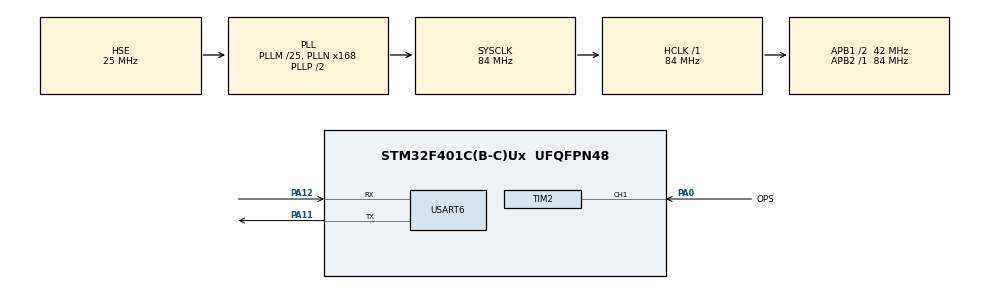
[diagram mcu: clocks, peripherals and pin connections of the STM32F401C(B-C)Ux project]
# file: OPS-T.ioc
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Mcu.Family=STM32F4
Mcu.Name=STM32F401C(B-C)Ux
Mcu.Package=UFQFPN48
NVIC.PriorityGroup=NVIC_PRIORITYGROUP_4
NVIC.TIM2_IRQn=true\:0\:0\:false\:false\:true\:true\:true\:true
PA0-WKUP.GPIO_Label=OPS
PA0-WKUP.Signal=S_TIM2_CH1_ETR
PA11.Mode=Asynchronous
PA11.Signal=USART6_TX
PA12.Mode=Asynchronous
PA12.Signal=USART6_RX
PA13.Mode=Serial_Wire
PA13.Signal=SYS_JTMS-SWDIO
PA14.Mode=Serial_Wire
PA14.Signal=SYS_JTCK-SWCLK
PH0\ -\ OSC_IN.Mode=HSE-External-Oscillator
PH0\ -\ OSC_IN.Signal=RCC_OSC_IN
PH1\ -\ OSC_OUT.Mode=HSE-External-Oscillator
PH1\ -\ OSC_OUT.Signal=RCC_OSC_OUT
ProjectManager.HeapSize=0x200
ProjectManager.StackSize=0x400
ProjectManager.TargetToolchain=STM32CubeIDE
RCC.48MHZClocksFreq_Value=42000000
RCC.AHBFreq_Value=84000000
RCC.APB1CLKDivider=RCC_HCLK_DIV2
RCC.APB1Freq_Value=42000000
RCC.APB1TimFreq_Value=84000000
RCC.APB2Freq_Value=84000000
RCC.APB2TimFreq_Value=84000000
RCC.CortexFreq_Value=84000000
RCC.HCLKFreq_Value=84000000
RCC.HSE_VALUE=25000000
RCC.HSI_VALUE=16000000
RCC.LSE_VALUE=32768
RCC.PLLM=25
RCC.PLLN=168
RCC.PLLSourceVirtual=RCC_PLLSOURCE_HSE
RCC.SYSCLKFreq_VALUE=84000000
RCC.SYSCLKSource=RCC_SYSCLKSOURCE_PLLCLK
RCC.VCOOutputFreq_Value=168000000
SH.S_TIM2_CH1_ETR.0=TIM2_CH1,PWM_Input_1
USART6.VirtualMode=VM_ASYNC
board=custom

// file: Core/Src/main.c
/* USER CODE BEGIN Header */
/**
 ******************************************************************************
 * @file           : main.c
 * @brief          : Main program body
 ******************************************************************************
 * @attention
 *
 * Copyright (c) 2025 STMicroelectronics.
 * All rights reserved.
 *
 * This software is licensed under terms that can be found in the LICENSE file
 * in the root directory of this software component.
 * If no LICENSE file comes with this software, it is provided AS-IS.
 *
 ******************************************************************************
 */
/* USER CODE END Header */
#include "main.h"

/* USER CODE BEGIN Includes */
#include <stdio.h>
#include <string.h>
/* USER CODE END Includes */

TIM_HandleTypeDef htim2;

UART_HandleTypeDef huart6;

/* USER CODE BEGIN PV */
uint8_t data_block[] = "Hello world\n";

// timer stuff:
float tick_time_sec = 0;
float tick_time_micros = 0;

/* USER CODE END PV */

void SystemClock_Config(void);
static void MX_GPIO_Init(void);
static void MX_USART6_UART_Init(void);
static void MX_TIM2_Init(void);
/* USER CODE BEGIN PFP */
void set_timer_globals(void);
float calculate_temperature(uint32_t ticks_count);
float calculate_pressure(uint32_t ticks_count);
eStatus calculate_sensor_status(uint32_t ticks_count);
/* USER CODE END PFP */

/* USER CODE BEGIN 0 */

sOps sensor1;

/* USER CODE END 0 */

int main(void) {

	/* MCU Configuration--------------------------------------------------------*/

	/* Reset of all peripherals, Initializes the Flash interface and the Systick. */
	HAL_Init();

	/* Configure the system clock */
	SystemClock_Config();

	/* Initialize all configured peripherals */
	MX_GPIO_Init();
	MX_USART6_UART_Init();
	MX_TIM2_Init();
	/* USER CODE BEGIN 2 */

	uint8_t sensor_data[128];
	set_timer_globals();

	sensor1.receiveStatus = waitForStatus;

	HAL_TIM_IC_Start_IT(&htim2, TIM_CHANNEL_1);
	HAL_TIM_IC_Start(&htim2, TIM_CHANNEL_2);

	/* USER CODE END 2 */

	/* Infinite loop */
	/* USER CODE BEGIN WHILE */
	while (1) {
		// HAL_UART_Transmit(&huart6, data_block, sizeof(data_block) - 1, 100);
		sprintf((char*) sensor_data, "Status: %d, Temperature: %.2f °C, Pressure: %.2f Bar\r\n",
				calculate_sensor_status(sensor1.statusTicks), calculate_temperature(sensor1.temperatureTicks),
				calculate_pressure(sensor1.pressureTicks));

		HAL_UART_Transmit(&huart6, (uint8_t*) sensor_data, strlen((char*) sensor_data), HAL_MAX_DELAY);

		HAL_Delay(1000);
		/* USER CODE END WHILE */

	}
}

void SystemClock_Config(void) {
	RCC_OscInitTypeDef RCC_OscInitStruct = { 0 };
	RCC_ClkInitTypeDef RCC_ClkInitStruct = { 0 };

	/** Configure the main internal regulator output voltage
	 */
	__HAL_RCC_PWR_CLK_ENABLE();
	__HAL_PWR_VOLTAGESCALING_CONFIG(PWR_REGULATOR_VOLTAGE_SCALE2);

	/** Initializes the RCC Oscillators according to the specified parameters
	 * in the RCC_OscInitTypeDef structure.
	 */
	RCC_OscInitStruct.OscillatorType = RCC_OSCILLATORTYPE_HSE;
	RCC_OscInitStruct.HSEState = RCC_HSE_ON;
	RCC_OscInitStruct.PLL.PLLState = RCC_PLL_ON;
	RCC_OscInitStruct.PLL.PLLSource = RCC_PLLSOURCE_HSE;
	RCC_OscInitStruct.PLL.PLLM = 25;
	RCC_OscInitStruct.PLL.PLLN = 168;
	RCC_OscInitStruct.PLL.PLLP = RCC_PLLP_DIV2;
	RCC_OscInitStruct.PLL.PLLQ = 4;
	if (HAL_RCC_OscConfig(&RCC_OscInitStruct) != HAL_OK) {
		Error_Handler();
	}

	/** Initializes the CPU, AHB and APB buses clocks
	 */
	RCC_ClkInitStruct.ClockType = RCC_CLOCKTYPE_HCLK | RCC_CLOCKTYPE_SYSCLK | RCC_CLOCKTYPE_PCLK1 | RCC_CLOCKTYPE_PCLK2;
	RCC_ClkInitStruct.SYSCLKSource = RCC_SYSCLKSOURCE_PLLCLK;
	RCC_ClkInitStruct.AHBCLKDivider = RCC_SYSCLK_DIV1;
	RCC_ClkInitStruct.APB1CLKDivider = RCC_HCLK_DIV2;
	RCC_ClkInitStruct.APB2CLKDivider = RCC_HCLK_DIV1;

	if (HAL_RCC_ClockConfig(&RCC_ClkInitStruct, FLASH_LATENCY_2) != HAL_OK) {
		Error_Handler();
	}
}

static void MX_TIM2_Init(void) {

	TIM_SlaveConfigTypeDef sSlaveConfig = { 0 };
	TIM_IC_InitTypeDef sConfigIC = { 0 };
	TIM_MasterConfigTypeDef sMasterConfig = { 0 };

	htim2.Instance = TIM2;
	htim2.Init.Prescaler = 0;
	htim2.Init.CounterMode = TIM_COUNTERMODE_UP;
	htim2.Init.Period = 4294967295;
	htim2.Init.ClockDivision = TIM_CLOCKDIVISION_DIV1;
	htim2.Init.AutoReloadPreload = TIM_AUTORELOAD_PRELOAD_DISABLE;
	if (HAL_TIM_IC_Init(&htim2) != HAL_OK) {
		Error_Handler();
	}
	sSlaveConfig.SlaveMode = TIM_SLAVEMODE_RESET;
	sSlaveConfig.InputTrigger = TIM_TS_TI1FP1;
	sSlaveConfig.TriggerPolarity = TIM_INPUTCHANNELPOLARITY_RISING;
	sSlaveConfig.TriggerPrescaler = TIM_ICPSC_DIV1;
	sSlaveConfig.TriggerFilter = 0;
	if (HAL_TIM_SlaveConfigSynchro(&htim2, &sSlaveConfig) != HAL_OK) {
		Error_Handler();
	}
	sConfigIC.ICPolarity = TIM_INPUTCHANNELPOLARITY_RISING;
	sConfigIC.ICSelection = TIM_ICSELECTION_DIRECTTI;
	sConfigIC.ICPrescaler = TIM_ICPSC_DIV1;
	sConfigIC.ICFilter = 0;
	if (HAL_TIM_IC_ConfigChannel(&htim2, &sConfigIC, TIM_CHANNEL_1) != HAL_OK) {
		Error_Handler();
	}
	sConfigIC.ICPolarity = TIM_INPUTCHANNELPOLARITY_FALLING;
	sConfigIC.ICSelection = TIM_ICSELECTION_INDIRECTTI;
	if (HAL_TIM_IC_ConfigChannel(&htim2, &sConfigIC, TIM_CHANNEL_2) != HAL_OK) {
		Error_Handler();
	}
	sMasterConfig.MasterOutputTrigger = TIM_TRGO_RESET;
	sMasterConfig.MasterSlaveMode = TIM_MASTERSLAVEMODE_DISABLE;
	if (HAL_TIMEx_MasterConfigSynchronization(&htim2, &sMasterConfig) != HAL_OK) {
		Error_Handler();
	}

}

static void MX_USART6_UART_Init(void) {

	huart6.Instance = USART6;
	huart6.Init.BaudRate = 115200;
	huart6.Init.WordLength = UART_WORDLENGTH_8B;
	huart6.Init.StopBits = UART_STOPBITS_1;
	huart6.Init.Parity = UART_PARITY_NONE;
	huart6.Init.Mode = UART_MODE_TX_RX;
	huart6.Init.HwFlowCtl = UART_HWCONTROL_NONE;
	huart6.Init.OverSampling = UART_OVERSAMPLING_16;
	if (HAL_UART_Init(&huart6) != HAL_OK) {
		Error_Handler();
	}

}

static void MX_GPIO_Init(void) {

	/* GPIO Ports Clock Enable */
	__HAL_RCC_GPIOH_CLK_ENABLE();
	__HAL_RCC_GPIOA_CLK_ENABLE();

}

/* USER CODE BEGIN 4 */

void set_timer_globals(void) {
	uint32_t apb1_frequency = HAL_RCC_GetPCLK1Freq();
	uint32_t timclk;

	if ((RCC->CFGR & RCC_CFGR_PPRE1) != RCC_CFGR_PPRE1_DIV1)
		timclk = apb1_frequency * 2;
	else
		timclk = apb1_frequency;

	uint32_t prescaler = htim2.Init.Prescaler;
	float timer_freq = (float) timclk / (prescaler + 1);
	tick_time_sec = 1.0f / timer_freq;  // seconds per tick
	tick_time_micros = tick_time_sec * 1000000;  // seconds per tick
}

float calculate_temperature(uint32_t ticks_count) {
	float time_us = ticks_count * tick_time_micros;

	return (time_us - 896.0f) / 19.2f;
}

float calculate_pressure(uint32_t ticks_count) {
	float time_us = ticks_count * tick_time_micros;
	return (time_us + 64.0f) / 384.0f;
}

eStatus calculate_sensor_status(uint32_t ticks_count) {
	// in status field is the tolerance +/- 25µs
	float time_us = ticks_count * tick_time_micros;
	eStatus retVal;

	if (time_us >= 231 && time_us <= 281)
		retVal = okStatus;

	if (time_us >= 359 && time_us <= 409)
		retVal = pressureFailure;

	if (time_us >= 487 && time_us <= 537)
		retVal = temperatureFailure;

	if (time_us >= 615 && time_us <= 665)
		retVal = hardwareFailure;

	return retVal;

}

void HAL_TIM_IC_CaptureCallback(TIM_HandleTypeDef *htim) {

	if (htim->Instance == TIM2) {
		/*
		 * timer_channel_1 fires the interrupt
		 * timer_channel_1 will be triggered on RISING edge (package length)
		 * timer_channel_2 will be triggered on FALLING edge (pwm value)
		 *
		 */
		uint32_t ticks_full = HAL_TIM_ReadCapturedValue(htim, TIM_CHANNEL_1) + 2;	// time between two rising edges
		uint32_t ticks_high = HAL_TIM_ReadCapturedValue(htim, TIM_CHANNEL_2) + 2;	// time between rising and falling edges

		float time_full = ticks_full * tick_time_micros;

		if (time_full > 1000 && time_full < 1100) {
			// we received the status field of the message
			sensor1.statusTicks = ticks_high;
			sensor1.receiveStatus = statusReceived;
		}

		else if (time_full > 3900 && sensor1.receiveStatus == statusReceived) {
			// now we are receiving the temperature field of the message
			sensor1.temperatureTicks = ticks_high;
			sensor1.receiveStatus = temperatureReceived;
		}

		else if (time_full > 3900 && sensor1.receiveStatus == temperatureReceived) {
			// now we are receiving the pressure field of the message
			sensor1.pressureTicks = ticks_high;
			sensor1.receiveStatus = pressureReceived;
		}
	}
}

/* USER CODE END 4 */

void Error_Handler(void) {
	__disable_irq();
	while (1) {
	}
}
